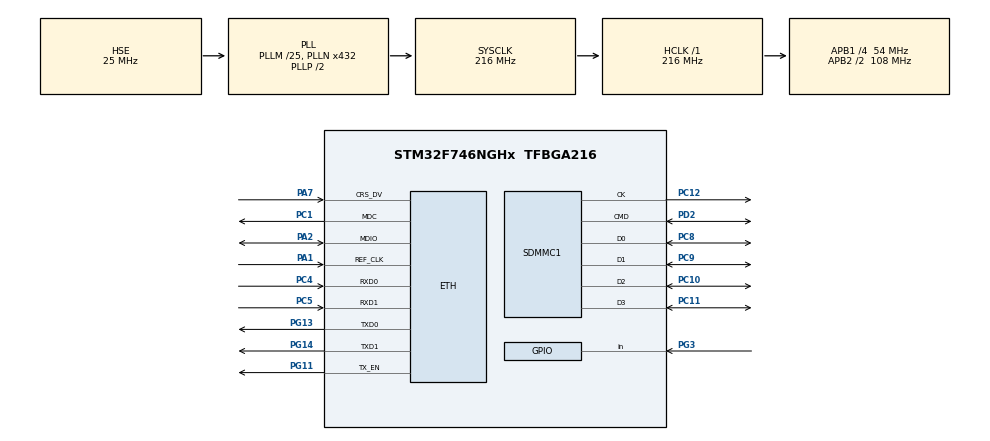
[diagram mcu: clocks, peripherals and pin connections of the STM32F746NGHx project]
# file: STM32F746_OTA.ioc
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ETH.MediaInterface=ETH_MEDIA_INTERFACE_RMII
FATFS.BSP.number=1
FATFS._USE_MUTEX=1
FATFS0.BSP.STBoard=false
FATFS0.BSP.api=Unknown
FATFS0.BSP.i2caddr=0
FATFS0.BSP.instance=PG3
FATFS0.BSP.ip=GPIO
FATFS0.BSP.mode=Input
FATFS0.BSP.name=Detect_SDIO
FATFS0.BSP.solution=PG3
FREERTOS.Tasks01=defaultTask,24,128,StartDefaultTask,Default,NULL,Dynamic,NULL,NULL
FREERTOS.configENABLE_FPU=1
FREERTOS.configTOTAL_HEAP_SIZE=131072
LWIP.Version=v2.1.2_Cube
Mcu.Family=STM32F7
Mcu.Name=STM32F746NGHx
Mcu.Package=TFBGA216
NVIC.ETH_IRQn=true\:5\:0\:false\:false\:true\:true\:false\:true
NVIC.PriorityGroup=NVIC_PRIORITYGROUP_4
NVIC.SDMMC1_IRQn=true\:5\:0\:false\:false\:true\:true\:true\:true
NVIC.TIM1_UP_TIM10_IRQn=true\:0\:0\:false\:false\:true\:false\:false\:true
NVIC.TimeBase=TIM1_UP_TIM10_IRQn
NVIC.TimeBaseIP=TIM1
PA1.Mode=RMII
PA1.Signal=ETH_REF_CLK
PA2.Mode=RMII
PA2.Signal=ETH_MDIO
PA7.Mode=RMII
PA7.Signal=ETH_CRS_DV
PC1.Mode=RMII
PC1.Signal=ETH_MDC
PC10.Mode=SD_4_bits_Wide_bus
PC10.Signal=SDMMC1_D2
PC11.Mode=SD_4_bits_Wide_bus
PC11.Signal=SDMMC1_D3
PC12.Mode=SD_4_bits_Wide_bus
PC12.Signal=SDMMC1_CK
PC4.Mode=RMII
PC4.Signal=ETH_RXD0
PC5.Mode=RMII
PC5.Signal=ETH_RXD1
PC8.Mode=SD_4_bits_Wide_bus
PC8.Signal=SDMMC1_D0
PC9.Mode=SD_4_bits_Wide_bus
PC9.Signal=SDMMC1_D1
PD2.Mode=SD_4_bits_Wide_bus
PD2.Signal=SDMMC1_CMD
PG11.Mode=RMII
PG11.Signal=ETH_TX_EN
PG13.Mode=RMII
PG13.Signal=ETH_TXD0
PG14.Mode=RMII
PG14.Signal=ETH_TXD1
PG3.Signal=GPIO_Input
PH0/OSC_IN.Mode=HSE-External-Oscillator
PH0/OSC_IN.Signal=RCC_OSC_IN
PH1/OSC_OUT.Mode=HSE-External-Oscillator
PH1/OSC_OUT.Signal=RCC_OSC_OUT
ProjectManager.HeapSize=0x200
ProjectManager.StackSize=0x400
ProjectManager.TargetToolchain=SW4STM32
RCC.AHBFreq_Value=216000000
RCC.APB1CLKDivider=RCC_HCLK_DIV4
RCC.APB1Freq_Value=54000000
RCC.APB1TimFreq_Value=108000000
RCC.APB2CLKDivider=RCC_HCLK_DIV2
RCC.APB2Freq_Value=108000000
RCC.APB2TimFreq_Value=216000000
RCC.CortexFreq_Value=216000000
RCC.HCLKFreq_Value=216000000
RCC.HSE_VALUE=25000000
RCC.HSI_VALUE=16000000
RCC.LSE_VALUE=32768
RCC.PLLM=25
RCC.PLLN=432
RCC.PLLQ=9
RCC.PLLSourceVirtual=RCC_PLLSOURCE_HSE
RCC.SDMMCClockSelection=RCC_SDMMC1CLKSOURCE_CLK48
RCC.SYSCLKFreq_VALUE=216000000
RCC.SYSCLKSource=RCC_SYSCLKSOURCE_PLLCLK
RCC.USBFreq_Value=48000000
RCC.VCOOutputFreq_Value=432000000
VP_CRC_VS_CRC.Mode=CRC_Activate
VP_FATFS_VS_SDIO.Mode=SDIO
VP_FREERTOS_VS_CMSIS_V2.Mode=CMSIS_V2
VP_LWIP_VS_Enabled.Mode=Enabled
VP_MBEDTLS_VS_MBEDTLS.Mode=Enabled
VP_RNG_VS_RNG.Mode=RNG_Activate
VP_SYS_VS_tim1.Mode=TIM1
board=custom

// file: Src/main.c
/* USER CODE BEGIN Header */
/**
  ******************************************************************************
  * @file           : main.c
  * @brief          : Main program body
  ******************************************************************************
  * @attention
  *
  * <h2><center>&copy; Copyright (c) 2019 STMicroelectronics.
  * All rights reserved.</center></h2>
  *
  * This software component is licensed by ST under Ultimate Liberty license
  * SLA0044, the "License"; You may not use this file except in compliance with
  * the License. You may obtain a copy of the License at:
  *                             www.st.com/SLA0044
  *
  ******************************************************************************
  */
/* USER CODE END Header */

#include "main.h"
#include "cmsis_os.h"
#include "fatfs.h"
#include "mbedtls.h"

/* USER CODE BEGIN PD */
osThreadId_t DHCP_ThreadId;
osThreadId_t TLS_ThreadId;
/* USER CODE END PD */

CRC_HandleTypeDef hcrc;

RNG_HandleTypeDef hrng;

SD_HandleTypeDef hsd1;

/* Definitions for defaultTask */
osThreadId_t defaultTaskHandle;
const osThreadAttr_t defaultTask_attributes = {
  .name = "defaultTask",
  .priority = (osPriority_t) osPriorityNormal,
  .stack_size = 128 * 4
};

void SystemClock_Config(void);
static void MX_GPIO_Init(void);
static void MX_CRC_Init(void);
static void MX_RNG_Init(void);
static void MX_SDMMC1_SD_Init(void);
void StartDefaultTask(void *argument);

void Fat_Error_Handler(FRESULT valor);

/* USER CODE BEGIN PFP */
void DHCP_Thread(void *argument);
void OTA(void *argument);
/* USER CODE END PFP */

int main(void)
{

  /* MCU Configuration--------------------------------------------------------*/

  /* Reset of all peripherals, Initializes the Flash interface and the Systick. */
  HAL_Init();

  /* Configure the system clock */
  SystemClock_Config();

  /* Initialize all configured peripherals */
  MX_GPIO_Init();
  MX_CRC_Init();
  MX_RNG_Init();
  MX_SDMMC1_SD_Init();
  /* Up to user define the empty MX_MBEDTLS_Init() function located in mbedtls.c file */
  //MX_FATFS_Init();

  /* Init scheduler */
  osKernelInitialize();

  /* Create the thread(s) */
  /* creation of defaultTask */
  defaultTaskHandle = osThreadNew(StartDefaultTask, NULL, &defaultTask_attributes);

  /* USER CODE BEGIN RTOS_THREADS */
  const osThreadAttr_t DHCPTask_attributes = {
    .name = "DHCPTask",
    .priority = (osPriority_t) osPriorityAboveNormal,
    .stack_size = 4*256
  };
  DHCP_ThreadId = osThreadNew(DHCP_Thread, NULL, &DHCPTask_attributes);

  const osThreadAttr_t TLSTask_attributes = {
    .name = "OTATask",
    .priority = (osPriority_t) osPriorityHigh,
    .stack_size = 12*256
  };
  TLS_ThreadId = osThreadNew(OTA, NULL, &TLSTask_attributes);

  /* USER CODE END RTOS_THREADS */

  /* Start scheduler */
  osKernelStart();

  /* We should never get here as control is now taken by the scheduler */
  /* Infinite loop */
  while (1)
  {

  }
}

void SystemClock_Config(void)
{
  RCC_OscInitTypeDef RCC_OscInitStruct = {0};
  RCC_ClkInitTypeDef RCC_ClkInitStruct = {0};
  RCC_PeriphCLKInitTypeDef PeriphClkInitStruct = {0};

  /** Configure the main internal regulator output voltage
  */
  __HAL_RCC_PWR_CLK_ENABLE();
  __HAL_PWR_VOLTAGESCALING_CONFIG(PWR_REGULATOR_VOLTAGE_SCALE1);
  /** Initializes the CPU, AHB and APB busses clocks
  */
  RCC_OscInitStruct.OscillatorType = RCC_OSCILLATORTYPE_HSE;
  RCC_OscInitStruct.HSEState = RCC_HSE_ON;
  RCC_OscInitStruct.PLL.PLLState = RCC_PLL_ON;
  RCC_OscInitStruct.PLL.PLLSource = RCC_PLLSOURCE_HSE;
  RCC_OscInitStruct.PLL.PLLM = 25;
  RCC_OscInitStruct.PLL.PLLN = 432;
  RCC_OscInitStruct.PLL.PLLP = RCC_PLLP_DIV2;
  RCC_OscInitStruct.PLL.PLLQ = 9;
  if (HAL_RCC_OscConfig(&RCC_OscInitStruct) != HAL_OK)
  {
    Error_Handler();
  }
  /** Activate the Over-Drive mode
  */
  if (HAL_PWREx_EnableOverDrive() != HAL_OK)
  {
    Error_Handler();
  }
  /** Initializes the CPU, AHB and APB busses clocks
  */
  RCC_ClkInitStruct.ClockType = RCC_CLOCKTYPE_HCLK|RCC_CLOCKTYPE_SYSCLK
                              |RCC_CLOCKTYPE_PCLK1|RCC_CLOCKTYPE_PCLK2;
  RCC_ClkInitStruct.SYSCLKSource = RCC_SYSCLKSOURCE_PLLCLK;
  RCC_ClkInitStruct.AHBCLKDivider = RCC_SYSCLK_DIV1;
  RCC_ClkInitStruct.APB1CLKDivider = RCC_HCLK_DIV4;
  RCC_ClkInitStruct.APB2CLKDivider = RCC_HCLK_DIV2;

  if (HAL_RCC_ClockConfig(&RCC_ClkInitStruct, FLASH_LATENCY_7) != HAL_OK)
  {
    Error_Handler();
  }
  PeriphClkInitStruct.PeriphClockSelection = RCC_PERIPHCLK_SDMMC1|RCC_PERIPHCLK_CLK48;
  PeriphClkInitStruct.Clk48ClockSelection = RCC_CLK48SOURCE_PLL;
  PeriphClkInitStruct.Sdmmc1ClockSelection = RCC_SDMMC1CLKSOURCE_CLK48;
  if (HAL_RCCEx_PeriphCLKConfig(&PeriphClkInitStruct) != HAL_OK)
  {
    Error_Handler();
  }
}

static void MX_CRC_Init(void)
{

  hcrc.Instance = CRC;
  hcrc.Init.DefaultPolynomialUse = DEFAULT_POLYNOMIAL_ENABLE;
  hcrc.Init.DefaultInitValueUse = DEFAULT_INIT_VALUE_ENABLE;
  hcrc.Init.InputDataInversionMode = CRC_INPUTDATA_INVERSION_NONE;
  hcrc.Init.OutputDataInversionMode = CRC_OUTPUTDATA_INVERSION_DISABLE;
  hcrc.InputDataFormat = CRC_INPUTDATA_FORMAT_BYTES;
  if (HAL_CRC_Init(&hcrc) != HAL_OK)
  {
    Error_Handler();
  }

}

static void MX_RNG_Init(void)
{

  hrng.Instance = RNG;
  if (HAL_RNG_Init(&hrng) != HAL_OK)
  {
    Error_Handler();
  }

}

static void MX_SDMMC1_SD_Init(void)
{

  hsd1.Instance = SDMMC1;
  hsd1.Init.ClockEdge = SDMMC_CLOCK_EDGE_RISING;
  hsd1.Init.ClockBypass = SDMMC_CLOCK_BYPASS_DISABLE;
  hsd1.Init.ClockPowerSave = SDMMC_CLOCK_POWER_SAVE_DISABLE;
  hsd1.Init.BusWide = SDMMC_BUS_WIDE_1B;
  hsd1.Init.HardwareFlowControl = SDMMC_HARDWARE_FLOW_CONTROL_DISABLE;
  hsd1.Init.ClockDiv = 32;

}

static void MX_GPIO_Init(void)
{
  GPIO_InitTypeDef GPIO_InitStruct = {0};

  /* GPIO Ports Clock Enable */
  __HAL_RCC_GPIOG_CLK_ENABLE();
  __HAL_RCC_GPIOC_CLK_ENABLE();
  __HAL_RCC_GPIOD_CLK_ENABLE();
  __HAL_RCC_GPIOH_CLK_ENABLE();
  __HAL_RCC_GPIOA_CLK_ENABLE();

  /*Configure GPIO pin : PC13 */
  GPIO_InitStruct.Pin = GPIO_PIN_13;
  GPIO_InitStruct.Mode = GPIO_MODE_INPUT;
  GPIO_InitStruct.Pull = GPIO_NOPULL;
  HAL_GPIO_Init(GPIOC, &GPIO_InitStruct);

}

/* USER CODE BEGIN 4 */
//uint8_t retSD; /* Return value for SD */
char SD_Path[4]; /* SD logical drive path */
//FATFS SDFatFS; /* File system object for SD logical drive */
//FIL SDFile; /* File object for SD */

FATFS fatfs;
FIL file;
uint8_t read_buffer[512];
BYTE work[512];
/* USER CODE END 4 */

void StartDefaultTask(void *argument)
{
  /* USER CODE BEGIN 5 */
	unsigned int size = 0;
	UARTPutString("FatFS started\n\r>>",17);
	if(FATFS_LinkDriver(&SD_Driver, SD_Path)!=0)
		UARTPutString("Link fail!\n\r>>",14);
	/* Terceiro argumento igual a 1 pede para montar agora o sistema de arquivos */
	//UARTPutString("Fazendo o mount\n\r\n\r>>",21);
	FRESULT res = f_mount(&SDFatFS, SDPath, 1);
	if (res != FR_OK) Fat_Error_Handler(res);
	//UARTPutString("Encerra FatFS_init\n\r\n\r>>",24);
	/*if (res == FR_OK){
		UARTPutString("passou do monut\n\r\n\r>>",21);
		res = f_open(&file, "teste.txt", FA_OPEN_EXISTING | FA_READ);

		if (res == FR_OK){
			//uint32_t file_size = f_size(&file);
			UARTPutString("passou file open\n\r\n\r>>",22);
			do{
				res=f_read(&file, read_buffer, 512, &size);

			}while(size != 0);
			UARTPutString("fechou arquivo\n\r\n\r>>",20);
			f_close(&file);
		} else Fat_Error_Handler(res);
	} else Fat_Error_Handler(res);*/
  /* Infinite loop */
  for(;;)
  {
    osDelay(1);
  }
  /* USER CODE END 5 */
}

 /**
  * @brief  Period elapsed callback in non blocking mode
  * @note   This function is called  when TIM1 interrupt took place, inside
  * HAL_TIM_IRQHandler(). It makes a direct call to HAL_IncTick() to increment
  * a global variable "uwTick" used as application time base.
  * @param  htim : TIM handle
  * @retval None
  */
void HAL_TIM_PeriodElapsedCallback(TIM_HandleTypeDef *htim)
{
  if (htim->Instance == TIM1) {
    HAL_IncTick();
  }
}

void Error_Handler(void)
{
}

void Fat_Error_Handler(FRESULT valor)
{
  /* USER CODE BEGIN Error_Handler_Debug */
  /* User can add his own implementation to report the HAL error return state */
	UARTPutString("Erro FatFS: ",12);
	switch(valor){
		case(0):
					UARTPutString("FR_OK\n\r",7);
		break;
		case(1):
					UARTPutString("FR_DISK_ERR\n\r",13);
		break;
		case(2):
					UARTPutString("FR_INT_ERR\n\r",12);
		break;
		case(3):
					UARTPutString("FR_NOT_READY\n\r",14);
		break;
		case(4):
					UARTPutString("FR_NO_FILE\n\r",12);
		break;
		case(5):
					UARTPutString("FR_NO_PATH\n\r",12);
		break;
		case(6):
					UARTPutString("FR_INVALID_NAME\n\r",17);
		break;
		case(7):
					UARTPutString("FR_DENIED\n\r",11);
		break;
		case(8):
					UARTPutString("FR_EXIST\n\r",10);
		break;
		case(9):
					UARTPutString("FR_INVALID_OBJECT\n\r",19);
		break;
		case(10):
					UARTPutString("FR_WRITE_PROTECTED\n\r",20);
		break;
		case(11):
					UARTPutString("FR_INVALID_DRIVE\n\r",18);
		break;
		case(12):
					UARTPutString("FR_NOT_ENABLED\n\r",16);
		break;
		case(13):
					UARTPutString("FR_NO_FILESYSTEM\n\r",18);
		break;
		case(14):
					UARTPutString("FR_MKFS_ABORTED\n\r",17);
		break;
		case(15):
					UARTPutString("FR_TIMEOUT\n\r",12);
		break;
		case(16):
					UARTPutString("FR_LOCKED\n\r",11);
		break;
		case(17):
					UARTPutString("FR_NOT_ENOUGH_CORE\n\r",20);
		break;
		case(18):
					UARTPutString("FR_TOO_MANY_OPEN_FILES\n\r",24);
		break;
		case(19):
					UARTPutString("FR_INVALID_PARAMETER\n\r",22);
		break;
	}
  /* USER CODE END Error_Handler_Debug */
}

/************************ (C) COPYRIGHT STMicroelectronics *****END OF FILE****/
